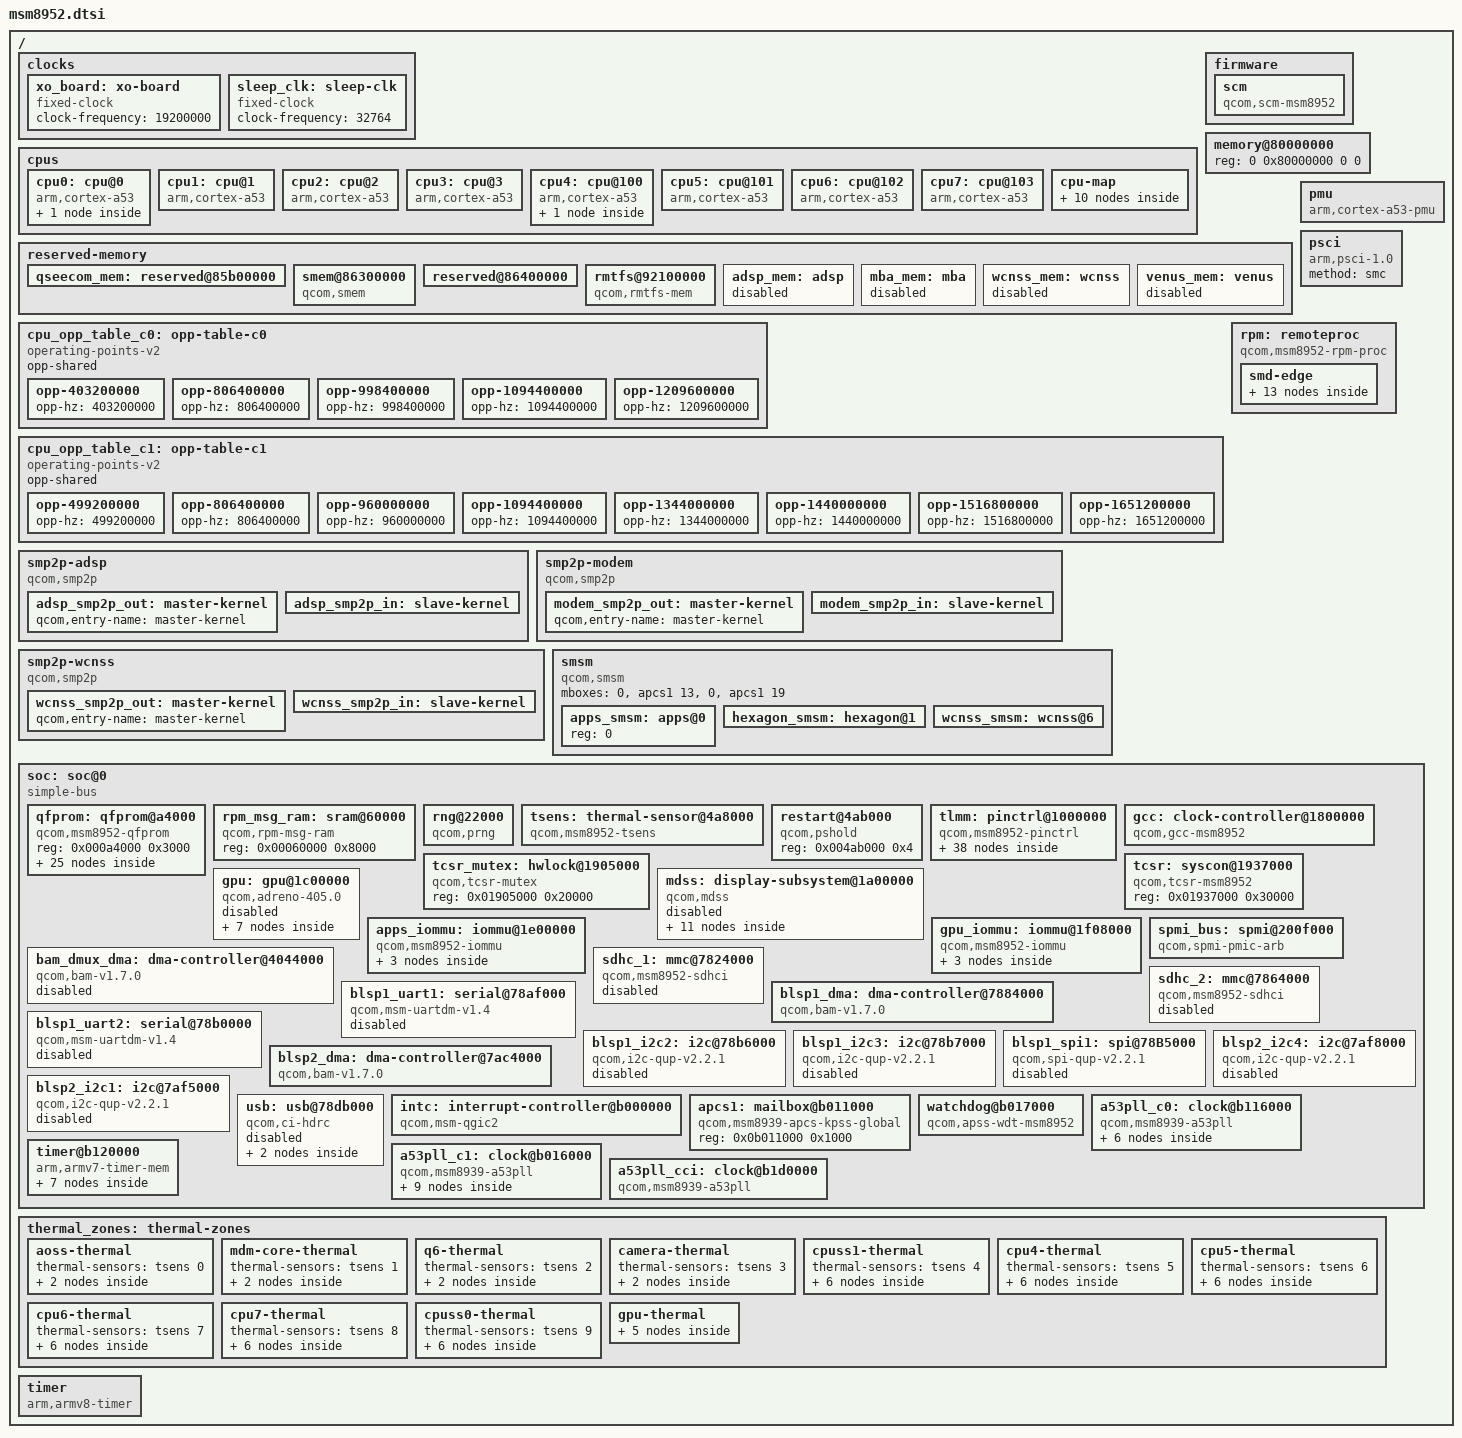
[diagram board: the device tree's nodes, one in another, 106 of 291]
// SPDX-License-Identifier: BSD-3-Clause
/*
 * Copyright (c) 2023, Dang Huynh <danct12@riseup.net>
 */

#include <dt-bindings/clock/qcom,dsi-phy-28nm.h>
#include <dt-bindings/clock/qcom,gcc-msm8952.h>
#include <dt-bindings/reset/qcom,gcc-msm8952.h>
#include <dt-bindings/clock/qcom,rpmcc.h>
#include <dt-bindings/interrupt-controller/arm-gic.h>
#include <dt-bindings/power/qcom-rpmpd.h>
#include <dt-bindings/thermal/thermal.h>
#include <dt-bindings/arm/qcom,ids.h>

/ {
	qcom,msm-id = <QCOM_ID_MSM8952 0x0>;
	interrupt-parent = <&intc>;

	#address-cells = <2>;
	#size-cells = <2>;

	clocks {
		xo_board: xo-board {
			compatible = "fixed-clock";
			#clock-cells = <0>;
			clock-frequency = <19200000>;
		};

		sleep_clk: sleep-clk {
			compatible = "fixed-clock";
			#clock-cells = <0>;
			clock-frequency = <32764>;
		};
	};

	cpus {
		#address-cells = <1>;
		#size-cells = <0>;

		cpu0: cpu@0 {
			compatible = "arm,cortex-a53";
			reg = <0x0>;
			device_type = "cpu";
			enable-method = "psci";
			operating-points-v2 = <&cpu_opp_table_c0>;
			next-level-cache = <&l2_0>;
			#cooling-cells = <2>;

			l2_0: l2-cache {
				compatible = "cache";
				cache-level = <2>;
				cache-size = <0x40000>;
				cache-unified;
			};
		};

		cpu1: cpu@1 {
			compatible = "arm,cortex-a53";
			reg = <0x1>;
			device_type = "cpu";
			enable-method = "psci";
			operating-points-v2 = <&cpu_opp_table_c0>;
			next-level-cache = <&l2_0>;
			#cooling-cells = <2>;
		};

		cpu2: cpu@2 {
			compatible = "arm,cortex-a53";
			reg = <0x2>;
			device_type = "cpu";
			enable-method = "psci";
			operating-points-v2 = <&cpu_opp_table_c0>;
			next-level-cache = <&l2_0>;
			#cooling-cells = <2>;
		};

		cpu3: cpu@3 {
			compatible = "arm,cortex-a53";
			reg = <0x3>;
			device_type = "cpu";
			enable-method = "psci";
			operating-points-v2 = <&cpu_opp_table_c0>;
			next-level-cache = <&l2_0>;
			#cooling-cells = <2>;
		};

		cpu4: cpu@100 {
			compatible = "arm,cortex-a53";
			reg = <0x100>;
			device_type = "cpu";
			next-level-cache = <&l2_1>;
			enable-method = "psci";
			operating-points-v2 = <&cpu_opp_table_c1>;
			#cooling-cells = <2>;

			l2_1: l2-cache {
				compatible = "cache";
				cache-level = <2>;
				cache-size = <0x80000>;
				cache-unified;
			};
		};

		cpu5: cpu@101 {
			compatible = "arm,cortex-a53";
			reg = <0x101>;
			device_type = "cpu";
			next-level-cache = <&l2_1>;
			enable-method = "psci";
			operating-points-v2 = <&cpu_opp_table_c1>;
			#cooling-cells = <2>;
		};

		cpu6: cpu@102 {
			compatible = "arm,cortex-a53";
			reg = <0x102>;
			device_type = "cpu";
			next-level-cache = <&l2_1>;
			enable-method = "psci";
			operating-points-v2 = <&cpu_opp_table_c1>;
			#cooling-cells = <2>;
		};

		cpu7: cpu@103 {
			compatible = "arm,cortex-a53";
			reg = <0x103>;
			device_type = "cpu";
			next-level-cache = <&l2_1>;
			enable-method = "psci";
			operating-points-v2 = <&cpu_opp_table_c1>;
			#cooling-cells = <2>;
		};

		cpu-map {
			/* Little Cores */
			cluster0 {
				core0 {
					cpu = <&cpu0>;
				};

				core1 {
					cpu = <&cpu1>;
				};

				core2 {
					cpu = <&cpu2>;
				};

				core3 {
					cpu = <&cpu3>;
				};
			};

			/* Big Cores */
			cluster1 {
				core0 {
					cpu = <&cpu4>;
				};

				core1 {
					cpu = <&cpu5>;
				};

				core2 {
					cpu = <&cpu6>;
				};

				core3 {
					cpu = <&cpu7>;
				};
			};
		};
	};

	firmware {
		scm: scm {
			compatible = "qcom,scm-msm8952", "qcom,scm";
			clocks = <&gcc GCC_CRYPTO_CLK>,
				 <&gcc GCC_CRYPTO_AXI_CLK>,
				 <&gcc GCC_CRYPTO_AHB_CLK>;
			clock-names = "core",
					  "bus",
					  "iface";
			#reset-cells = <1>;

			qcom,dload-mode = <&tcsr 0x6100>;
		};
	};

	memory@80000000 {
		/* We expect the bootloader to fill in the reg */
		reg = <0 0x80000000 0 0>;
		device_type = "memory";
	};

	reserved-memory {
		ranges;
		#address-cells = <2>;
		#size-cells = <2>;

		qseecom_mem: reserved@85b00000 {
			reg = <0x0 0x85b00000 0x0 0x800000>;
			no-map;
		};

		smem@86300000 {
			compatible = "qcom,smem";
			reg = <0x0 0x86300000 0x0 0x100000>;
			no-map;

			hwlocks = <&tcsr_mutex 3>;
			qcom,rpm-msg-ram = <&rpm_msg_ram>;
		};

		reserved@86400000 {
			reg = <0x0 0x86400000 0x0 0x400000>;
			no-map;
		};

		rmtfs@92100000 {
			compatible = "qcom,rmtfs-mem";
			reg = <0x0 0x92100000 0x0 0x180000>;
			no-map;

			qcom,client-id = <1>;
		};

		adsp_mem: adsp {
			size = <0x0 0x1100000>;
			alignment = <0x0 0x100000>;
			alloc-ranges = <0x0 0x86800000 0x0 0x8000000>;
			no-map;
			status = "disabled";
		};

		mba_mem: mba {
			size = <0x0 0x100000>;
			alignment = <0x0 0x100000>;
			alloc-ranges = <0x0 0x86800000 0x0 0x8000000>;
			no-map;
			status = "disabled";
		};

		wcnss_mem: wcnss {
			size = <0x0 0x700000>;
			alignment = <0x0 0x100000>;
			alloc-ranges = <0x0 0x86800000 0x0 0x8000000>;
			no-map;
			status = "disabled";
		};

		venus_mem: venus {
			size = <0x0 0x400000>;
			alignment = <0x0 0x100000>;
			alloc-ranges = <0x0 0x86800000 0x0 0x8000000>;
			no-map;
			status = "disabled";
		};
	};

	cpu_opp_table_c0: opp-table-c0 {
		compatible = "operating-points-v2";
		opp-shared;

		opp-403200000 {
			opp-hz = /bits/ 64 <403200000>;
		};

		opp-806400000 {
			opp-hz = /bits/ 64 <806400000>;
		};

		opp-998400000 {
			opp-hz = /bits/ 64 <998400000>;
		};

		opp-1094400000 {
			opp-hz = /bits/ 64 <1094400000>;
		};

		opp-1209600000 {
			opp-hz = /bits/ 64 <1209600000>;
		};
	};

	cpu_opp_table_c1: opp-table-c1 {
		compatible = "operating-points-v2";
		opp-shared;

		opp-499200000 {
			opp-hz = /bits/ 64 <499200000>;
		};

		opp-806400000 {
			opp-hz = /bits/ 64 <806400000>;
		};

		opp-960000000 {
			opp-hz = /bits/ 64 <960000000>;
		};

		opp-1094400000 {
			opp-hz = /bits/ 64 <1094400000>;
		};

		opp-1344000000 {
			opp-hz = /bits/ 64 <1344000000>;
		};

		opp-1440000000 {
			opp-hz = /bits/ 64 <1440000000>;
		};

		opp-1516800000 {
			opp-hz = /bits/ 64 <1516800000>;
		};

		opp-1651200000 {
			opp-hz = /bits/ 64 <1651200000>;
		};
	};

	pmu {
		compatible = "arm,cortex-a53-pmu";
		interrupts = <GIC_PPI 7 (GIC_CPU_MASK_SIMPLE(8) | IRQ_TYPE_LEVEL_HIGH)>;
	};

	psci {
		compatible = "arm,psci-1.0";
		method = "smc";
	};

	rpm: remoteproc {
		compatible = "qcom,msm8952-rpm-proc", "qcom,rpm-proc";

		smd-edge {
			interrupts = <GIC_SPI 168 IRQ_TYPE_EDGE_RISING>;
			qcom,ipc = <&apcs1 8 0>;
			qcom,smd-edge = <15>;

			rpm_requests: rpm-requests {
				compatible = "qcom,rpm-msm8952", "qcom,smd-rpm";
				qcom,smd-channels = "rpm_requests";

				rpmcc: clock-controller {
					compatible = "qcom,rpmcc-msm8952", "qcom,rpmcc";
					#clock-cells = <1>;
					clocks = <&xo_board>;
					clock-names = "xo";
				};

				rpmpd: power-controller {
					compatible = "qcom,msm8952-rpmpd";
					#power-domain-cells = <1>;
					operating-points-v2 = <&rpmpd_opp_table>;

					rpmpd_opp_table: opp-table {
						compatible = "operating-points-v2";

						rpmpd_opp_ret: opp1 {
							opp-level = <RPM_SMD_LEVEL_RETENTION>;
						};

						rpmpd_opp_ret_plus: opp2 {
							opp-level = <RPM_SMD_LEVEL_RETENTION_PLUS>;
						};

						rpmpd_opp_min_svs: opp3 {
							opp-level = <RPM_SMD_LEVEL_MIN_SVS>;
						};

						rpmpd_opp_low_svs: opp4 {
							opp-level = <RPM_SMD_LEVEL_LOW_SVS>;
						};

						rpmpd_opp_svs: opp5 {
							opp-level = <RPM_SMD_LEVEL_SVS>;
						};

						rpmpd_opp_svs_plus: opp6 {
							opp-level = <RPM_SMD_LEVEL_SVS_PLUS>;
						};

						rpmpd_opp_nom: opp7 {
							opp-level = <RPM_SMD_LEVEL_NOM>;
						};

						rpmpd_opp_nom_plus: opp8 {
							opp-level = <RPM_SMD_LEVEL_NOM_PLUS>;
						};

						rpmpd_opp_turbo: opp9 {
							opp-level = <RPM_SMD_LEVEL_TURBO>;
						};
					};
				};
			};
		};
	};

	smp2p-adsp {
		compatible = "qcom,smp2p";
		qcom,smem = <443>, <429>;

		interrupts = <GIC_SPI 291 IRQ_TYPE_EDGE_RISING>;

		mboxes = <&apcs1 10>;

		qcom,local-pid = <0>;
		qcom,remote-pid = <2>;

		adsp_smp2p_out: master-kernel {
			qcom,entry-name = "master-kernel";

			#qcom,smem-state-cells = <1>;
		};

		adsp_smp2p_in: slave-kernel {
			qcom,entry-name = "slave-kernel";

			interrupt-controller;
			#interrupt-cells = <2>;
		};
	};

	smp2p-modem {
		compatible = "qcom,smp2p";
		qcom,smem = <435>, <428>;

		interrupts = <GIC_SPI 27 IRQ_TYPE_EDGE_RISING>;

		mboxes = <&apcs1 14>;

		qcom,local-pid = <0>;
		qcom,remote-pid = <1>;

		modem_smp2p_out: master-kernel {
			qcom,entry-name = "master-kernel";

			#qcom,smem-state-cells = <1>;
		};

		modem_smp2p_in: slave-kernel {
			qcom,entry-name = "slave-kernel";

			interrupt-controller;
			#interrupt-cells = <2>;
		};
	};

	smp2p-wcnss {
		compatible = "qcom,smp2p";
		qcom,smem = <451>, <431>;

		interrupts = <GIC_SPI 143 IRQ_TYPE_EDGE_RISING>;

		mboxes = <&apcs1 18>;

		qcom,local-pid = <0>;
		qcom,remote-pid = <4>;

		wcnss_smp2p_out: master-kernel {
			qcom,entry-name = "master-kernel";

			#qcom,smem-state-cells = <1>;
		};

		wcnss_smp2p_in: slave-kernel {
			qcom,entry-name = "slave-kernel";

			interrupt-controller;
			#interrupt-cells = <2>;
		};
	};

	smsm {
		compatible = "qcom,smsm";

		#address-cells = <1>;
		#size-cells = <0>;

		mboxes = <0>, <&apcs1 13>, <0>, <&apcs1 19>;

		apps_smsm: apps@0 {
			reg = <0>;

			#qcom,smem-state-cells = <1>;
		};

		hexagon_smsm: hexagon@1 {
			reg = <1>;
			interrupts = <GIC_SPI 26 IRQ_TYPE_EDGE_RISING>;

			interrupt-controller;
			#interrupt-cells = <2>;
		};

		wcnss_smsm: wcnss@6 {
			reg = <6>;
			interrupts = <GIC_SPI 144 IRQ_TYPE_EDGE_RISING>;

			interrupt-controller;
			#interrupt-cells = <2>;
		};
	};

	soc: soc@0 {
		compatible = "simple-bus";
		ranges = <0 0 0 0xffffffff>;
		#address-cells = <1>;
		#size-cells = <1>;

		qfprom: qfprom@a4000 {
			compatible = "qcom,msm8952-qfprom", "qcom,qfprom";
			reg = <0x000a4000 0x3000>;
			#address-cells = <1>;
			#size-cells = <1>;

			tsens_base1: base1@1d8 {
				reg = <0x1d8 0x1>;
				bits = <0 8>;
			};

			tsens_s5_p1: s5-p1@1d9 {
				reg = <0x1d9 0x1>;
				bits = <0 6>;
			};

			tsens_s5_p2: s5-p2@1d9 {
				reg = <0x1d9 0x2>;
				bits = <6 6>;
			};

			tsens_s6_p1: s6-p1@1da {
				reg = <0x1da 0x2>;
				bits = <4 6>;
			};

			tsens_s6_p2: s6-p2@1db {
				reg = <0x1db 0x1>;
				bits = <2 6>;
			};

			tsens_s7_p1: s7-p1@1dc {
				reg = <0x1dc 0x1>;
				bits = <0 6>;
			};

			tsens_s7_p2: s7-p2@1dc {
				reg = <0x1dc 0x2>;
				bits = <6 6>;
			};

			tsens_s8_p1: s8-p1@1dd {
				reg = <0x1dd 0x2>;
				bits = <4 6>;
			};

			tsens_s8_p2: s8-p2@1de {
				reg = <0x1de 0x1>;
				bits = <2 6>;
			};

			tsens_base2: base2@1df {
				reg = <0x1df 0x1>;
				bits = <0 8>;
			};

			tsens_mode: mode@210 {
				reg = <0x210 0x1>;
				bits = <0 3>;
			};

			tsens_s0_p1: s0-p1@210 {
				reg = <0x210 0x2>;
				bits = <3 6>;
			};

			tsens_s0_p2: s0-p2@211 {
				reg = <0x211 0x1>;
				bits = <1 6>;
			};

			tsens_s1_p1: s1-p1@211 {
				reg = <0x211 0x2>;
				bits = <7 6>;
			};

			tsens_s1_p2: s1-p2@212 {
				reg = <0x212 0x2>;
				bits = <5 6>;
			};

			tsens_s2_p1: s2-p1@213 {
				reg = <0x213 0x2>;
				bits = <3 6>;
			};

			tsens_s2_p2: s2-p2@214 {
				reg = <0x214 0x1>;
				bits = <1 6>;
			};

			tsens_s3_p1: s3-p1@214 {
				reg = <0x214 0x2>;
				bits = <7 6>;
			};

			tsens_s3_p2: s3-p2@215 {
				reg = <0x215 0x2>;
				bits = <5 6>;
			};

			tsens_s4_p1: s4-p1@216 {
				reg = <0x216 0x2>;
				bits = <3 6>;
			};

			tsens_s4_p2: s4-p2@217 {
				reg = <0x217 0x1>;
				bits = <1 6>;
			};

			tsens_s9_p1: s9-p1@230 {
				reg = <0x230 0x1>;
				bits = <0 6>;
			};

			tsens_s9_p2: s9-p2@230 {
				reg = <0x230 0x2>;
				bits = <6 6>;
			};

			tsens_s10_p1: s10-p1@231 {
				reg = <0x231 0x2>;
				bits = <4 6>;
			};

			tsens_s10_p2: s10-p2@232 {
				reg = <0x232 0x1>;
				bits = <2 6>;
			};
		};

		rpm_msg_ram: sram@60000 {
			compatible = "qcom,rpm-msg-ram";
			reg = <0x00060000 0x8000>;
		};

		rng@22000 {
			compatible = "qcom,prng";
			reg = <0x00022000 0x140>;
			clocks = <&gcc GCC_PRNG_AHB_CLK>;
			clock-names = "core";
		};

		tsens: thermal-sensor@4a8000 {
			compatible = "qcom,msm8952-tsens", "qcom,tsens-v0_1";
			reg = <0x04a8000 0x2000>,
				  <0x05c000  0x1000>;
			interrupts = <GIC_SPI 184 IRQ_TYPE_LEVEL_HIGH>;
			interrupt-names = "uplow";
			nvmem-cells = <&tsens_mode>,
					  <&tsens_base1>, <&tsens_base2>,
					  <&tsens_s0_p1>, <&tsens_s0_p2>,
					  <&tsens_s1_p1>, <&tsens_s1_p2>,
					  <&tsens_s2_p1>, <&tsens_s2_p2>,
					  <&tsens_s3_p1>, <&tsens_s3_p2>,
					  <&tsens_s4_p1>, <&tsens_s4_p2>,
					  <&tsens_s5_p1>, <&tsens_s5_p2>,
					  <&tsens_s6_p1>, <&tsens_s6_p2>,
					  <&tsens_s7_p1>, <&tsens_s7_p2>,
					  <&tsens_s8_p1>, <&tsens_s8_p2>,
					  <&tsens_s9_p1>, <&tsens_s9_p2>,
					  <&tsens_s10_p1>, <&tsens_s10_p2>;
			nvmem-cell-names = "mode",
					   "base1", "base2",
					   "s0_p1", "s0_p2",
					   "s1_p1", "s1_p2",
					   "s2_p1", "s2_p2",
					   "s3_p1", "s3_p2",
					   "s4_p1", "s4_p2",
					   "s5_p1", "s5_p2",
					   "s6_p1", "s6_p2",
					   "s7_p1", "s7_p2",
					   "s8_p1", "s8_p2",
					   "s9_p1", "s9_p2",
					   "s10_p1", "s10_p2";
			#qcom,sensors = <11>;
			#thermal-sensor-cells = <1>;
		};

		restart@4ab000 {
			compatible = "qcom,pshold";
			reg = <0x004ab000 0x4>;
		};

		tlmm: pinctrl@1000000 {
			compatible = "qcom,msm8952-pinctrl";
			reg = <0x01000000 0x300000>;
			interrupts = <GIC_SPI 208 IRQ_TYPE_LEVEL_HIGH>;
			gpio-controller;
			gpio-ranges = <&tlmm 0 0 134>;
			#gpio-cells = <2>;
			interrupt-controller;
			#interrupt-cells = <2>;

			blsp1_i2c2_default: blsp1-i2c2-default-state {
				pins = "gpio6", "gpio7";
				function = "blsp_i2c2";
				drive-strength = <2>;
				bias-disable;
			};

			blsp1_i2c2_sleep: blsp1-i2c2-sleep-state {
				pins = "gpio6", "gpio7";
				function = "gpio";
				drive-strength = <2>;
				bias-disable;
			};

			blsp1_i2c3_default: blsp1-i2c3-default-state {
				pins = "gpio10", "gpio11";
				function = "blsp_i2c3";
				drive-strength = <2>;
				bias-disable;
			};

			blsp1_i2c3_sleep: blsp1-i2c3-sleep-state {
				pins = "gpio10", "gpio11";
				function = "gpio";
				drive-strength = <2>;
				bias-disable;
			};

			blsp2_i2c4_default: blsp2-i2c4-default-state {
				pins = "gpio98", "gpio99";
				function = "blsp_i2c8";
				drive-strength = <2>;
				bias-disable;
			};

			blsp2_i2c4_sleep: blsp2-i2c4-sleep-state {
				pins = "gpio98", "gpio99";
				function = "gpio";
				drive-strength = <2>;
				bias-disable;
			};

			blsp2_i2c1_default: blsp2-i2c1-default-state {
				pins = "gpio18", "gpio19";
				function = "blsp_i2c5";
				drive-strength = <2>;
				bias-disable;
			};

			blsp2_i2c1_sleep: blsp2-i2c1-sleep-state {
				pins = "gpio18", "gpio19";
				function = "gpio";
				drive-strength = <2>;
				bias-disable;
			};

			blsp_spi1_default: spi1-default-state {
				spi-pins {
					pins = "gpio0", "gpio1", "gpio3";
					function = "blsp_spi1";
					drive-strength = <12>;
					bias-disable;
				};

				cs-pins {
					pins = "gpio2";
					function = "blsp_spi1";
					drive-strength = <2>;
					bias-disable;
				};
			};

			blsp_spi1_sleep: spi0-sleep-state {
				spi-pins {
					pins = "gpio0", "gpio1", "gpio3";
					function = "gpio";
					drive-strength = <2>;
					bias-pull-down;
				};

				cs-pins {
					pins = "gpio2";
					function = "gpio";
					drive-strength = <2>;
					bias-disable;
				};
			};

			blsp1_uart1_default: blsp1-uart1-default-state {
				pins = "gpio0", "gpio1", "gpio2", "gpio3";
				function = "blsp_uart1";
				drive-strength = <2>;
				bias-disable;
			};

			blsp1_uart1_sleep: blsp1-uart1-sleep-state {
				pins = "gpio0", "gpio1", "gpio2", "gpio3";
				function = "gpio";
				drive-strength = <2>;
				bias-disable;
			};


			blsp1_uart1_console_default: blsp-uart1-console-default-state {
				tx-pins {
					pins = "gpio0";
					function = "blsp_uart1";
					drive-strength = <16>;
					bias-disable;
					bootph-all;
				};

				rx-pins {
					pins = "gpio1";
					function = "blsp_uart1";
					drive-strength = <16>;
					bias-pull-up;
					bootph-all;
				};
			};

			blsp1_uart1_console_sleep: blsp-uart1-console-sleep-state {
				pins = "gpio0", "gpio1";
				function = "gpio";
				drive-strength = <2>;
				bias-pull-down;
			};

			blsp1_uart2_default: blsp1-uart2-default-state {
				pins = "gpio4", "gpio5";
				function = "blsp_uart2";
				drive-strength = <2>;
				bias-disable;
			};

			blsp1_uart2_sleep: blsp1-uart2-sleep-state {
				pins = "gpio4", "gpio5";
				function = "gpio";
				drive-strength = <2>;
				bias-pull-down;
			};

			sdc1_clk_on: sdc1-clk-on-state {
				pins = "sdc1_clk";
				bias-disable;
				drive-strength = <16>;
			};

			sdc1_clk_off: sdc1-clk-off-state {
				pins = "sdc1_clk";
				bias-disable;
				drive-strength = <2>;
			};

			sdc1_cmd_on: sdc1-cmd-on-state {
				pins = "sdc1_cmd";
				bias-disable;
				drive-strength = <10>;
			};

			sdc1_cmd_off: sdc1-cmd-off-state {
				pins = "sdc1_cmd";
				bias-disable;
				drive-strength = <2>;
			};

			sdc1_data_on: sdc1-data-on-state {
				pins = "sdc1_data";
				bias-pull-up;
				drive-strength = <10>;
			};

			sdc1_data_off: sdc1-data-off-state {
				pins = "sdc1_data";
				bias-pull-up;
				drive-strength = <2>;
			};

			sdc1_rclk_on: sdc1-rclk-on-state {
				pins = "sdc1_rclk";
				bias-pull-down;
			};

			sdc1_rclk_off: sdc1-rclk-off-state {
				pins = "sdc1_rclk";
				bias-pull-down;
			};

			sdc2_clk_on: sdc2-clk-on-state {
				pins = "sdc2_clk";
				drive-strength = <16>;
				bias-disable;
			};

			sdc2_clk_off: sdc2-clk-off-state {
				pins = "sdc2_clk";
				bias-disable;
				drive-strength = <2>;
			};

			sdc2_cmd_on: sdc2-cmd-on-state {
				pins = "sdc2_cmd";
				bias-pull-up;
				drive-strength = <10>;
			};

			sdc2_cmd_off: sdc2-cmd-off-state {
				pins = "sdc2_cmd";
				bias-pull-up;
				drive-strength = <2>;
			};

			sdc2_data_on: sdc2-data-on-state {
				pins = "sdc2_data";
				bias-pull-up;
				drive-strength = <10>;
			};

			sdc2_data_off: sdc2-data-off-state {
				pins = "sdc2_data";
				bias-pull-up;
				drive-strength = <2>;
			};

			sdc2_cd_on: cd-on-state {
				pins = "gpio67";
				function = "gpio";
				drive-strength = <2>;
				bias-pull-up;
			};

			sdc2_cd_off: cd-off-state {
				pins = "gpio67";
				function = "gpio";
				drive-strength = <2>;
				bias-disable;
			};

		};

		gcc: clock-controller@1800000 {
			compatible = "qcom,gcc-msm8952";
			reg = <0x01800000 0x80000>;
			#clock-cells = <1>;
			#reset-cells = <1>;
			#power-domain-cells = <1>;
			clocks = <&rpmcc RPM_SMD_XO_CLK_SRC>,
				 <&sleep_clk>,
				 <&mdss_dsi0_phy DSI_PIXEL_PLL_CLK>,
				 <&mdss_dsi0_phy DSI_BYTE_PLL_CLK>,
				 <0>,
				 <0>,
				 <0>;
			clock-names = "xo",
					  "sleep_clk",
					  "dsi0pll",
					  "dsi0pllbyte",
					  "ext_mclk",
					  "ext_pri_i2s",
					  "ext_sec_i2s";
		};

		tcsr_mutex: hwlock@1905000 {
			compatible = "qcom,tcsr-mutex";
			reg = <0x01905000 0x20000>;
			#hwlock-cells = <1>;
		};

		tcsr: syscon@1937000 {
			compatible = "qcom,tcsr-msm8952", "syscon";
			reg = <0x01937000 0x30000>;
		};

		mdss: display-subsystem@1a00000 {
			status = "disabled";
			compatible = "qcom,mdss";
			reg = <0x01a00000 0x1000>,
				  <0x01ac8000 0x3000>;
			reg-names = "mdss_phys", "vbif_phys";

			power-domains = <&gcc MDSS_GDSC>;

			clocks = <&gcc GCC_MDSS_AHB_CLK>,
					 <&gcc GCC_MDSS_AXI_CLK>,
					 <&gcc GCC_MDSS_VSYNC_CLK>;
			clock-names = "iface",
						  "bus",
						  "vsync";

			interrupts = <GIC_SPI 72 IRQ_TYPE_LEVEL_HIGH>;

			resets = <&gcc GCC_MDSS_BCR>;

			interrupt-controller;
			#interrupt-cells = <1>;

			#address-cells = <1>;
			#size-cells = <1>;
			ranges;

			mdss_mdp: display-controller@1a01000 {
				compatible = "qcom,msm8952-mdp5", "qcom,mdp5";
				reg = <0x01a01000 0x89000>;
				reg-names = "mdp_phys";

				interrupt-parent = <&mdss>;
				interrupts = <0>;

				clocks = <&gcc GCC_MDSS_AHB_CLK>,
						 <&gcc GCC_MDSS_AXI_CLK>,
						 <&gcc GCC_MDSS_MDP_CLK>,
						 <&gcc GCC_MDSS_VSYNC_CLK>,
						 <&gcc GCC_MDP_TBU_CLK>;
				clock-names = "iface",
							  "bus",
							  "core",
							  "vsync",
							  "tbu";

				iommus = <&apps_iommu 4>;

				ports {
					#address-cells = <1>;
					#size-cells = <0>;

					port@0 {
						reg = <0>;
						mdss_mdp_intf1_out: endpoint {
							remote-endpoint = <&mdss_dsi0_in>;
						};
					};
				};
			};

			mdss_dsi0: dsi@1a98000 {
				compatible = "qcom,msm8916-dsi-ctrl",
							 "qcom,mdss-dsi-ctrl";
				reg = <0x01a98000 0x25c>;
				reg-names = "dsi_ctrl";

				interrupt-parent = <&mdss>;
				interrupts = <4>;

				assigned-clocks = <&gcc BYTE0_CLK_SRC>,
								  <&gcc PCLK0_CLK_SRC>;
				assigned-clock-parents = <&mdss_dsi0_phy DSI_BYTE_PLL_CLK>,
										 <&mdss_dsi0_phy DSI_PIXEL_PLL_CLK>;

				clocks = <&gcc GCC_MDSS_MDP_CLK>,
						 <&gcc GCC_MDSS_AHB_CLK>,
						 <&gcc GCC_MDSS_AXI_CLK>,
						 <&gcc GCC_MDSS_BYTE0_CLK>,
						 <&gcc GCC_MDSS_PCLK0_CLK>,
						 <&gcc GCC_MDSS_ESC0_CLK>;
				clock-names = "mdp_core",
							  "iface",
							  "bus",
							  "byte",
							  "pixel",
							  "core";
				phys = <&mdss_dsi0_phy>;

				#address-cells = <1>;
				#size-cells = <0>;

				ports {
					#address-cells = <1>;
					#size-cells = <0>;

					port@0 {
						reg = <0>;
						mdss_dsi0_in: endpoint {
							remote-endpoint = <&mdss_mdp_intf1_out>;
						};
					};

					port@1 {
						reg = <1>;
						mdss_dsi0_out: endpoint {
						};
					};
				};
			};

			mdss_dsi0_phy: phy@1a98300 {
				compatible = "qcom,dsi-phy-28nm-lp";
				reg = <0x01a98300 0xd4>,
					  <0x01a98500 0x280>,
					  <0x01a98780 0x30>;
				reg-names = "dsi_pll",
							"dsi_phy",
							"dsi_phy_regulator";

				#clock-cells = <1>;
				#phy-cells = <0>;

				clocks = <&gcc GCC_MDSS_AHB_CLK>,
						 <&xo_board>;
				clock-names = "iface", "ref";
			};
		};

		gpu: gpu@1c00000 {
			compatible = "qcom,adreno-405.0", "qcom,adreno";
			reg = <0x01c00000 0x10000>;
			reg-names = "kgsl_3d0_reg_memory";
			interrupts = <GIC_SPI 33 IRQ_TYPE_LEVEL_HIGH>;
			interrupt-names = "kgsl_3d0_irq";
			clock-names = "core",
						  "iface",
						  "mem",
						  "mem_iface",
						  "alt_mem_iface",
						  "gfx3d",
						  "rbbmtimer";
			clocks = <&gcc GCC_OXILI_GFX3D_CLK>,
					 <&gcc GCC_OXILI_AHB_CLK>,
					 <&gcc GCC_OXILI_GMEM_CLK>,
					 <&gcc GCC_BIMC_GFX_CLK>,
					 <&gcc GCC_BIMC_GPU_CLK>,
					 <&gcc GFX3D_CLK_SRC>,
					 <&gcc GCC_OXILI_TIMER_CLK>;
			power-domains = <&gcc OXILI_GDSC>;
			operating-points-v2 = <&opp_table>;
			iommus = <&gpu_iommu 0>, <&gpu_iommu 1>;
			#cooling-cells = <2>;

			status = "disabled";

			opp_table: opp-table {
				compatible = "operating-points-v2";

				opp-550000000 {
					opp-hz = /bits/ 64 <550000000>;
				};

				opp-500000000 {
					opp-hz = /bits/ 64 <500000000>;
				};

				opp-465000000 {
					opp-hz = /bits/ 64 <465000000>;
				};

				opp-400000000 {
					opp-hz = /bits/ 64 <400000000>;
				};

				opp-240000000 {
					opp-hz = /bits/ 64 <240000000>;
				};

				opp-19200000 {
					opp-hz = /bits/ 64 <19200000>;
				};
			};
		};

		apps_iommu: iommu@1e00000 {
			compatible = "qcom,msm8952-iommu", "qcom,msm-iommu-v2";
			reg = <0x01e00000 0x40000>;
			ranges = <0 0x01e20000 0x20000>;

			clocks = <&gcc GCC_SMMU_CFG_CLK>,
					 <&gcc GCC_APSS_TCU_CLK>;
			clock-names = "iface", "bus";

			qcom,iommu-secure-id = <17>;

			#address-cells = <1>;
			#size-cells = <1>;
			#iommu-cells = <1>;

			/* VFE */
			iommu-ctx@15000 {
				compatible = "qcom,msm-iommu-v2-ns";
				reg = <0x15000 0x1000>;
				qcom,ctx-asid = <20>;
				interrupts = <GIC_SPI 113 IRQ_TYPE_LEVEL_HIGH>;
			};

			/* VENUS NS */
			iommu-ctx@16000 {
				compatible = "qcom,msm-iommu-v2-ns";
				reg = <0x16000 0x1000>;
				qcom,ctx-asid = <21>;
				interrupts = <GIC_SPI 114 IRQ_TYPE_LEVEL_HIGH>;
			};

			/* MDP0 */
			iommu-ctx@17000 {
				compatible = "qcom,msm-iommu-v2-ns";
				reg = <0x17000 0x1000>;
				qcom,ctx-asid = <22>;
				interrupts = <GIC_SPI 115 IRQ_TYPE_LEVEL_HIGH>;
			};
		};

		gpu_iommu: iommu@1f08000 {
			compatible = "qcom,msm8952-iommu", "qcom,msm-iommu-v2";
			ranges = <0 0x01f08000 0x8000>;

			clocks = <&gcc GCC_SMMU_CFG_CLK>,
					 <&gcc GCC_GFX_TCU_CLK>;
			clock-names = "iface", "bus";

			qcom,iommu-secure-id = <18>;

			#address-cells = <1>;
			#size-cells = <1>;
			#iommu-cells = <1>;

			/* gfx3d user */
			iommu-ctx@0 {
				compatible = "qcom,msm-iommu-v2-ns";
				reg = <0x0 0x1000>;
				qcom,ctx-asid = <0>;
				interrupts = <GIC_SPI 240 IRQ_TYPE_LEVEL_HIGH>;
			};

			/* gfx3d secure */
			iommu-ctx@1000 {
				compatible = "qcom,msm-iommu-v2-sec";
				reg = <0x1000 0x1000>;
				qcom,ctx-asid = <2>;
				interrupts = <GIC_SPI 241 IRQ_TYPE_LEVEL_HIGH>;
			};

			/* gfx3d priv */
			iommu-ctx@3000 {
				compatible = "qcom,msm-iommu-v2-sec";
				reg = <0x3000 0x1000>;
				qcom,ctx-asid = <1>;
				interrupts = <GIC_SPI 245 IRQ_TYPE_LEVEL_HIGH>;
			};
		};

		spmi_bus: spmi@200f000 {
			compatible = "qcom,spmi-pmic-arb";
			reg = <0x0200f000 0x001000>,
				  <0x02400000 0x800000>,
				  <0x02c00000 0x800000>,
				  <0x03800000 0x200000>,
				  <0x0200a000 0x002100>;
			reg-names = "core",
					"chnls",
					"obsrvr",
					"intr",
					"cnfg";
			interrupt-names = "periph_irq";
			interrupts = <GIC_SPI 190 IRQ_TYPE_LEVEL_HIGH>;
			qcom,ee = <0>;
			qcom,channel = <0>;
			#address-cells = <2>;
			#size-cells = <0>;
			interrupt-controller;
			#interrupt-cells = <4>;
		};

		bam_dmux_dma: dma-controller@4044000 {
			compatible = "qcom,bam-v1.7.0";
			reg = <0x04044000 0x19000>;
			interrupts = <GIC_SPI 162 IRQ_TYPE_LEVEL_HIGH>;
			#dma-cells = <1>;
			qcom,ee = <0>;

			num-channels = <6>;
			qcom,num-ees = <1>;
			qcom,powered-remotely;

			status = "disabled";
		};

		sdhc_1: mmc@7824000 {
			compatible = "qcom,msm8952-sdhci", "qcom,sdhci-msm-v4";
			reg = <0x07824900 0x500>, <0x07824000 0x800>;
			reg-names = "hc", "core";

			interrupts = <GIC_SPI 123 IRQ_TYPE_LEVEL_HIGH>,
					 <GIC_SPI 138 IRQ_TYPE_LEVEL_HIGH>;
			interrupt-names = "hc_irq", "pwr_irq";

			clocks = <&gcc GCC_SDCC1_AHB_CLK>,
				 <&gcc GCC_SDCC1_APPS_CLK>,
				 <&rpmcc RPM_SMD_XO_CLK_SRC>;
			clock-names = "iface", "core", "xo";

			pinctrl-names = "default", "sleep";
			pinctrl-0 = <&sdc1_clk_on &sdc1_cmd_on &sdc1_data_on &sdc1_rclk_on>;
			pinctrl-1 = <&sdc1_clk_off &sdc1_cmd_off &sdc1_data_off &sdc1_rclk_off>;

			mmc-hs400-1_8v;
			mmc-hs200-1_8v;
			mmc-ddr-1_8v;
			bus-width = <8>;
			non-removable;

			status = "disabled";
		};

		sdhc_2: mmc@7864000 {
			compatible = "qcom,msm8952-sdhci", "qcom,sdhci-msm-v4";
			reg = <0x07864900 0x11c>, <0x07864000 0x800>;
			reg-names = "hc", "core";

			interrupts = <GIC_SPI 125 IRQ_TYPE_LEVEL_HIGH>,
						 <GIC_SPI 221 IRQ_TYPE_LEVEL_HIGH>;
			interrupt-names = "hc_irq", "pwr_irq";

			clocks = <&gcc GCC_SDCC2_AHB_CLK>,
					 <&gcc GCC_SDCC2_APPS_CLK>,
					 <&rpmcc RPM_SMD_XO_CLK_SRC>;
			clock-names = "iface", "core", "xo";

			pinctrl-names = "default", "sleep";
			pinctrl-0 = <&sdc2_clk_on &sdc2_cmd_on &sdc2_data_on &sdc2_cd_on>;
			pinctrl-1 = <&sdc2_clk_off &sdc2_cmd_off &sdc2_data_off &sdc2_cd_off>;

			bus-width = <4>;

			status = "disabled";
		};

		blsp1_dma: dma-controller@7884000 {
			compatible = "qcom,bam-v1.7.0";
			reg = <0x07884000 0x1f000>;
			interrupts = <GIC_SPI 238 IRQ_TYPE_LEVEL_HIGH>;
			clocks = <&gcc GCC_BLSP1_AHB_CLK>;
			clock-names = "bam_clk";
			#dma-cells = <1>;
			qcom,ee = <0>;
			qcom,controlled-remotely;
		};

		blsp1_uart1: serial@78af000 {
			compatible = "qcom,msm-uartdm-v1.4", "qcom,msm-uartdm";
			reg = <0x078af000 0x1000>;
			interrupts = <GIC_SPI 107 IRQ_TYPE_LEVEL_HIGH>;
			clocks = <&gcc GCC_BLSP1_UART1_APPS_CLK>, <&gcc GCC_BLSP1_AHB_CLK>;
			clock-names = "core", "iface";
			dmas = <&blsp1_dma 0>, <&blsp1_dma 1>;
			dma-names = "tx", "rx";
			pinctrl-0 = <&blsp1_uart1_console_default>;
			pinctrl-1 = <&blsp1_uart1_console_sleep>;
			pinctrl-names = "default", "sleep";
			status = "disabled";
		};

		blsp1_uart2: serial@78b0000 {
			compatible = "qcom,msm-uartdm-v1.4", "qcom,msm-uartdm";
			reg = <0x078b0000 0x200>;
			interrupts = <GIC_SPI 108 IRQ_TYPE_LEVEL_HIGH>;
			clocks = <&gcc GCC_BLSP1_UART2_APPS_CLK>, <&gcc GCC_BLSP1_AHB_CLK>;
			clock-names = "core", "iface";
			dmas = <&blsp1_dma 2>, <&blsp1_dma 3>;
			dma-names = "tx", "rx";
			pinctrl-0 = <&blsp1_uart2_default>;
			pinctrl-1 = <&blsp1_uart2_sleep>;
			pinctrl-names = "default", "sleep";
			status = "disabled";
		};

		blsp1_i2c2: i2c@78b6000 {
			compatible = "qcom,i2c-qup-v2.2.1";
			reg = <0x078b6000 0x500>;
			interrupts = <GIC_SPI 96 IRQ_TYPE_LEVEL_HIGH>;
			clocks = <&gcc GCC_BLSP1_QUP2_I2C_APPS_CLK>, <&gcc GCC_BLSP1_AHB_CLK>;
			clock-names = "core", "iface";
			clock-frequency = <400000>;
			dmas = <&blsp1_dma 6>, <&blsp1_dma 7>;
			dma-names = "tx", "rx";
			pinctrl-0 = <&blsp1_i2c2_default>;
			pinctrl-1 = <&blsp1_i2c2_sleep>;
			pinctrl-names = "default", "sleep";
			#address-cells = <1>;
			#size-cells = <0>;
			status = "disabled";
		};

		blsp1_i2c3: i2c@78b7000 {
			compatible = "qcom,i2c-qup-v2.2.1";
			reg = <0x078b7000 0x600>;
			interrupts = <GIC_SPI 97 IRQ_TYPE_LEVEL_HIGH>;
			clocks = <&gcc GCC_BLSP1_QUP3_I2C_APPS_CLK>,
			         <&gcc GCC_BLSP1_AHB_CLK>;
			clock-names = "core", "iface";
			clock-frequency = <400000>;
			dmas = <&blsp1_dma 8>, <&blsp1_dma 9>;
			dma-names = "tx", "rx";
			pinctrl-0 = <&blsp1_i2c3_default>;
			pinctrl-1 = <&blsp1_i2c3_sleep>;
			pinctrl-names = "default", "sleep";
			#address-cells = <1>;
			#size-cells = <0>;
			status = "disabled";
		};

		blsp1_spi1: spi@78B5000 {
			compatible = "qcom,spi-qup-v2.2.1";
			reg = <0x078B5000 0x500>;
			interrupts = <GIC_SPI 95 IRQ_TYPE_LEVEL_HIGH>;
			clocks = <&gcc GCC_BLSP1_QUP1_SPI_APPS_CLK>, <&gcc GCC_BLSP1_AHB_CLK>;
			clock-names = "core", "iface";
			dmas = <&blsp1_dma 4>, <&blsp1_dma 5>;
			dma-names = "tx", "rx";
			pinctrl-names = "default", "sleep";
			pinctrl-0 = <&blsp_spi1_default>;
			pinctrl-1 = <&blsp_spi1_sleep>;
			#address-cells = <1>;
			#size-cells = <0>;
			status = "disabled";
		};

		blsp2_i2c4: i2c@7af8000 {
			compatible = "qcom,i2c-qup-v2.2.1";
			reg = <0x07af8000 0x600>;
			interrupts = <GIC_SPI 302 IRQ_TYPE_LEVEL_HIGH>;
			clocks = <&gcc GCC_BLSP2_QUP4_I2C_APPS_CLK>,
				 <&gcc GCC_BLSP2_AHB_CLK>;
			clock-names = "core", "iface";
			clock-frequency = <400000>;
			dmas = <&blsp2_dma 10>, <&blsp2_dma 11>;
			dma-names = "tx", "rx";
			pinctrl-0 = <&blsp2_i2c4_default>;
			pinctrl-1 = <&blsp2_i2c4_sleep>;
			pinctrl-names = "default", "sleep";
			#address-cells = <1>;
			#size-cells = <0>;
			status = "disabled";
		};

		blsp2_dma: dma-controller@7ac4000 {
			compatible = "qcom,bam-v1.7.0";
			reg = <0x07ac4000 0x1f000>;
			interrupts = <GIC_SPI 239 IRQ_TYPE_LEVEL_HIGH>;
			clocks = <&gcc GCC_BLSP2_AHB_CLK>;
			clock-names = "bam_clk";
			#dma-cells = <1>;
			qcom,ee = <0>;
			qcom,controlled-remotely;
		};

		blsp2_i2c1: i2c@7af5000 {
			compatible = "qcom,i2c-qup-v2.2.1";
			reg = <0x07af5000 0x1000>;
			interrupts = <GIC_SPI 299 IRQ_TYPE_LEVEL_HIGH>;
			clocks = <&gcc GCC_BLSP2_QUP1_I2C_APPS_CLK>,
				 <&gcc GCC_BLSP2_AHB_CLK>;
			clock-names = "core", "iface";
			clock-frequency = <400000>;
			dmas = <&blsp2_dma 4>, <&blsp2_dma 5>;
			dma-names = "tx", "rx";
			pinctrl-0 = <&blsp2_i2c1_default>;
			pinctrl-1 = <&blsp2_i2c1_sleep>;
			pinctrl-names = "default", "sleep";
			#address-cells = <1>;
			#size-cells = <0>;
			status = "disabled";
		};

		usb: usb@78db000 {
			compatible = "qcom,ci-hdrc";
			reg = <0x078db000 0x400>,
				  <0x06c000 0x200>;
			interrupts = <GIC_SPI 134 IRQ_TYPE_LEVEL_HIGH>,
						 <GIC_SPI 140 IRQ_TYPE_LEVEL_HIGH>;
			clocks = <&gcc GCC_USB_HS_AHB_CLK>,
					 <&gcc GCC_USB_HS_SYSTEM_CLK>;
			clock-names = "iface", "core";
			assigned-clocks = <&gcc GCC_USB_HS_SYSTEM_CLK>;
			assigned-clock-rates = <80000000>;
			resets = <&gcc GCC_USB_HS_BCR>;
			reset-names = "core";
			phy_type = "ulpi";
			dr_mode = "otg";
			hnp-disable;
			srp-disable;
			adp-disable;
			ahb-burst-config = <0>;
			phy-names = "usb-phy";
			phys = <&usb_hs_phy>;
			status = "disabled";
			#reset-cells = <1>;

			ulpi {
				usb_hs_phy: phy {
					compatible = "qcom,usb-hs-phy-msm8952",
								 "qcom,usb-hs-phy";
					#phy-cells = <0>;
					clocks = <&xo_board>, <&gcc GCC_USB2A_PHY_SLEEP_CLK>;
					clock-names = "ref", "sleep";
					resets = <&gcc GCC_USB2A_PHY_BCR>, <&usb 0>;
					reset-names = "phy", "por";
					qcom,init-seq = /bits/ 8 <0x0 0x73>,
									<0x1 0x68>,
									<0x2 0x24>;
				};
			};
		};

		intc: interrupt-controller@b000000 {
			compatible = "qcom,msm-qgic2";
			interrupt-controller;
			#interrupt-cells = <3>;
			reg = <0x0b000000 0x1000>,
				  <0x0b002000 0x1000>;
		};

		apcs1: mailbox@b011000 {
			compatible = "qcom,msm8939-apcs-kpss-global", "syscon";
			reg = <0x0b011000 0x1000>;
			#mbox-cells = <1>;
		};

		watchdog@b017000 {
			compatible = "qcom,apss-wdt-msm8952", "qcom,kpss-wdt";
			reg = <0x0b017000 0x1000>;
			clocks = <&sleep_clk>;
		};

		a53pll_c0: clock@b116000 {
			compatible = "qcom,msm8939-a53pll";
			reg = <0x0b116000 0x40>;
			clocks = <&xo_board>;
			clock-names = "xo";
			#clock-cells = <0>;
			operating-points-v2 = <&pll_opp_table_c0>;

			pll_opp_table_c0: opp-table {
				compatible = "operating-points-v2";

				opp-403200000 {
					opp-hz = /bits/ 64 <403200000>;
				};

				opp-806400000 {
					opp-hz = /bits/ 64 <806400000>;
				};

				opp-998400000 {
					opp-hz = /bits/ 64 <998400000>;
				};

				opp-1094400000 {
					opp-hz = /bits/ 64 <1094400000>;
				};

				opp-1209600000 {
					opp-hz = /bits/ 64 <1209600000>;
				};

			};
		};

		a53pll_c1: clock@b016000 {
			compatible = "qcom,msm8939-a53pll";
			reg = <0x0b016000 0x40>;
			clocks = <&xo_board>;
			clock-names = "xo";
			#clock-cells = <0>;
			operating-points-v2 = <&pll_opp_table_c1>;

			pll_opp_table_c1: opp-table {
				compatible = "operating-points-v2";

				opp-499200000 {
					opp-hz = /bits/ 64 <499200000>;
				};

				opp-806400000 {
					opp-hz = /bits/ 64 <806400000>;
				};

				opp-960000000 {
					opp-hz = /bits/ 64 <960000000>;
				};

				opp-1094400000 {
					opp-hz = /bits/ 64 <1094400000>;
				};

				opp-1344000000 {
					opp-hz = /bits/ 64 <1344000000>;
				};

				opp-1440000000 {
					opp-hz = /bits/ 64 <1440000000>;
				};

				opp-1516800000 {
					opp-hz = /bits/ 64 <1516800000>;
				};

				opp-1651200000 {
					opp-hz = /bits/ 64 <1651200000>;
				};
			};
		};

		a53pll_cci: clock@b1d0000 {
			compatible = "qcom,msm8939-a53pll";
			reg = <0x0b1d0000 0x40>;
			clocks = <&xo_board>;
			clock-names = "xo";
			#clock-cells = <0>;
		};

		timer@b120000 {
			compatible = "arm,armv7-timer-mem";
			reg = <0x0b120000 0x1000>;
			#address-cells = <1>;
			#size-cells = <1>;
			ranges;
			clock-frequency = <19200000>;

			frame@b121000 {
				reg = <0x0b121000 0x1000>, <0x0b122000 0x1000>;
				interrupts = <GIC_SPI 8 IRQ_TYPE_LEVEL_HIGH>,
							 <GIC_SPI 7 IRQ_TYPE_LEVEL_HIGH>;
				frame-number = <0>;
			};

			frame@b123000 {
				reg = <0x0b123000 0x1000>;
				interrupts = <GIC_SPI 9 IRQ_TYPE_LEVEL_HIGH>;
				frame-number = <1>;
				status = "disabled";
			};

			frame@b124000 {
				reg = <0x0b124000 0x1000>;
				interrupts = <GIC_SPI 10 IRQ_TYPE_LEVEL_HIGH>;
				frame-number = <2>;
				status = "disabled";
			};

			frame@b125000 {
				reg = <0x0b125000 0x1000>;
				interrupts = <GIC_SPI 11 IRQ_TYPE_LEVEL_HIGH>;
				frame-number = <3>;
				status = "disabled";
			};

			frame@b126000 {
				reg = <0x0b126000 0x1000>;
				interrupts = <GIC_SPI 12 IRQ_TYPE_LEVEL_HIGH>;
				frame-number = <4>;
				status = "disabled";
			};

			frame@b127000 {
				reg = <0x0b127000 0x1000>;
				interrupts = <GIC_SPI 13 IRQ_TYPE_LEVEL_HIGH>;
				frame-number = <5>;
				status = "disabled";
			};

			frame@b128000 {
				reg = <0x0b128000 0x1000>;
				interrupts = <GIC_SPI 14 IRQ_TYPE_LEVEL_HIGH>;
				frame-number = <6>;
				status = "disabled";
			};
		};
	};

	thermal_zones: thermal-zones {
		aoss-thermal {
			thermal-sensors = <&tsens 0>;

			trips {
				aoss_alert0: trip-point0 {
					temperature = <85000>;
					hysteresis = <2000>;
					type = "critical";
				};
			};
		};

		mdm-core-thermal {
			thermal-sensors = <&tsens 1>;

			trips {
				mdm_core_alert0: trip-point0 {
					temperature = <85000>;
					hysteresis = <2000>;
					type = "critical";
				};
			};
		};

		q6-thermal {
			thermal-sensors = <&tsens 2>;

			trips {
				q6_alert0: trip-point0 {
					temperature = <85000>;
					hysteresis = <2000>;
					type = "critical";
				};
			};
		};

		camera-thermal {
			thermal-sensors = <&tsens 3>;

			trips {
				camera_alert0: trip-point0 {
					temperature = <85000>;
					hysteresis = <2000>;
					type = "critical";
				};
			};
		};

		cpuss1-thermal {
			thermal-sensors = <&tsens 4>;

			cooling-maps {
				map0 {
					trip = <&cpuss1_alert0>;
					cooling-device = <&cpu4 THERMAL_NO_LIMIT THERMAL_NO_LIMIT>,
							 <&cpu5 THERMAL_NO_LIMIT THERMAL_NO_LIMIT>,
							 <&cpu6 THERMAL_NO_LIMIT THERMAL_NO_LIMIT>,
							 <&cpu7 THERMAL_NO_LIMIT THERMAL_NO_LIMIT>;
				};
			};

			trips {
				cpuss1_alert0: trip-point0 {
					temperature = <75000>;
					hysteresis = <2000>;
					type = "passive";
				};

				cpuss1_alert1: trip-point1 {
					temperature = <85000>;
					hysteresis = <2000>;
					type = "hot";
				};

				cpuss1_crit: cpuss1-crit {
					temperature = <100000>;
					hysteresis = <2000>;
					type = "critical";
				};
			};
		};

		cpu4-thermal {
			thermal-sensors = <&tsens 5>;

			cooling-maps {
				map0 {
					trip = <&cpu4_alert1>;
					cooling-device = <&cpu4 THERMAL_NO_LIMIT THERMAL_NO_LIMIT>,
							 <&cpu5 THERMAL_NO_LIMIT THERMAL_NO_LIMIT>,
							 <&cpu6 THERMAL_NO_LIMIT THERMAL_NO_LIMIT>,
							 <&cpu7 THERMAL_NO_LIMIT THERMAL_NO_LIMIT>;
				};
			};

			trips {
				cpu4_alert0: trip-point0 {
					temperature = <75000>;
					hysteresis = <2000>;
					type = "passive";
				};

				cpu4_alert1: trip-point1 {
					temperature = <85000>;
					hysteresis = <2000>;
					type = "hot";
				};

				cpu4_crit: cpu-crit {
					temperature = <100000>;
					hysteresis = <2000>;
					type = "critical";
				};
			};
		};

		cpu5-thermal {
			thermal-sensors = <&tsens 6>;

			cooling-maps {
				map0 {
					trip = <&cpu5_alert1>;
					cooling-device = <&cpu4 THERMAL_NO_LIMIT THERMAL_NO_LIMIT>,
							 <&cpu5 THERMAL_NO_LIMIT THERMAL_NO_LIMIT>,
							 <&cpu6 THERMAL_NO_LIMIT THERMAL_NO_LIMIT>,
							 <&cpu7 THERMAL_NO_LIMIT THERMAL_NO_LIMIT>;
				};
			};

			trips {
				cpu5_alert0: trip-point0 {
					temperature = <75000>;
					hysteresis = <2000>;
					type = "passive";
				};

				cpu5_alert1: trip-point1 {
					temperature = <85000>;
					hysteresis = <2000>;
					type = "hot";
				};

				cpu5_crit: cpu-crit {
					temperature = <100000>;
					hysteresis = <2000>;
					type = "critical";
				};
			};
		};

		cpu6-thermal {
			thermal-sensors = <&tsens 7>;

			cooling-maps {
				map0 {
					trip = <&cpu6_alert1>;
					cooling-device = <&cpu4 THERMAL_NO_LIMIT THERMAL_NO_LIMIT>,
							 <&cpu5 THERMAL_NO_LIMIT THERMAL_NO_LIMIT>,
							 <&cpu6 THERMAL_NO_LIMIT THERMAL_NO_LIMIT>,
							 <&cpu7 THERMAL_NO_LIMIT THERMAL_NO_LIMIT>;
				};
			};

			trips {
				cpu6_alert0: trip-point0 {
					temperature = <75000>;
					hysteresis = <2000>;
					type = "passive";
				};

				cpu6_alert1: trip-point1 {
					temperature = <85000>;
					hysteresis = <2000>;
					type = "hot";
				};

				cpu6_crit: cpu-crit {
					temperature = <100000>;
					hysteresis = <2000>;
					type = "critical";
				};
			};
		};

		cpu7-thermal {
			thermal-sensors = <&tsens 8>;

			cooling-maps {
				map0 {
					trip = <&cpu7_alert1>;
					cooling-device = <&cpu4 THERMAL_NO_LIMIT THERMAL_NO_LIMIT>,
							 <&cpu5 THERMAL_NO_LIMIT THERMAL_NO_LIMIT>,
							 <&cpu6 THERMAL_NO_LIMIT THERMAL_NO_LIMIT>,
							 <&cpu7 THERMAL_NO_LIMIT THERMAL_NO_LIMIT>;
				};
			};

			trips {
				cpu7_alert0: trip-point0 {
					temperature = <75000>;
					hysteresis = <2000>;
					type = "passive";
				};

				cpu7_alert1: trip-point1 {
					temperature = <85000>;
					hysteresis = <2000>;
					type = "hot";
				};

				cpu7_crit: cpu-crit {
					temperature = <100000>;
					hysteresis = <2000>;
					type = "critical";
				};
			};
		};

		cpuss0-thermal {
			thermal-sensors = <&tsens 9>;

			cooling-maps {
				map0 {
					trip = <&cpuss0_alert0>;
					cooling-device = <&cpu0 THERMAL_NO_LIMIT THERMAL_NO_LIMIT>,
							 <&cpu1 THERMAL_NO_LIMIT THERMAL_NO_LIMIT>,
							 <&cpu2 THERMAL_NO_LIMIT THERMAL_NO_LIMIT>,
							 <&cpu3 THERMAL_NO_LIMIT THERMAL_NO_LIMIT>;
				};
			};

			trips {
				cpuss0_alert0: trip-point0 {
					temperature = <75000>;
					hysteresis = <2000>;
					type = "passive";
				};

				cpuss0_alert1: trip-point1 {
					temperature = <85000>;
					hysteresis = <2000>;
					type = "hot";
				};

				cpuss0_crit: cpuss0-crit {
					temperature = <100000>;
					hysteresis = <2000>;
					type = "critical";
				};
			};
		};

		gpu-thermal {
			polling-delay-passive = <250>;

			thermal-sensors = <&tsens 10>;

			cooling-maps {
				map0 {
					trip = <&gpu_alert>;
					cooling-device = <&gpu THERMAL_NO_LIMIT THERMAL_NO_LIMIT>;
				};
			};

			trips {
				gpu_alert: trip-point0 {
					temperature = <70000>;
					hysteresis = <2000>;
					type = "passive";
				};

				gpu_crit: gpu-crit {
					temperature = <90000>;
					hysteresis = <2000>;
					type = "critical";
				};
			};
		};
	};

	timer {
		compatible = "arm,armv8-timer";
		interrupts = <GIC_PPI 2 (GIC_CPU_MASK_SIMPLE(8) | IRQ_TYPE_LEVEL_LOW)>,
				 <GIC_PPI 3 (GIC_CPU_MASK_SIMPLE(8) | IRQ_TYPE_LEVEL_LOW)>,
				 <GIC_PPI 4 (GIC_CPU_MASK_SIMPLE(8) | IRQ_TYPE_LEVEL_LOW)>,
				 <GIC_PPI 1 (GIC_CPU_MASK_SIMPLE(8) | IRQ_TYPE_LEVEL_LOW)>;
		clock-frequency = <19200000>;
	};
};

